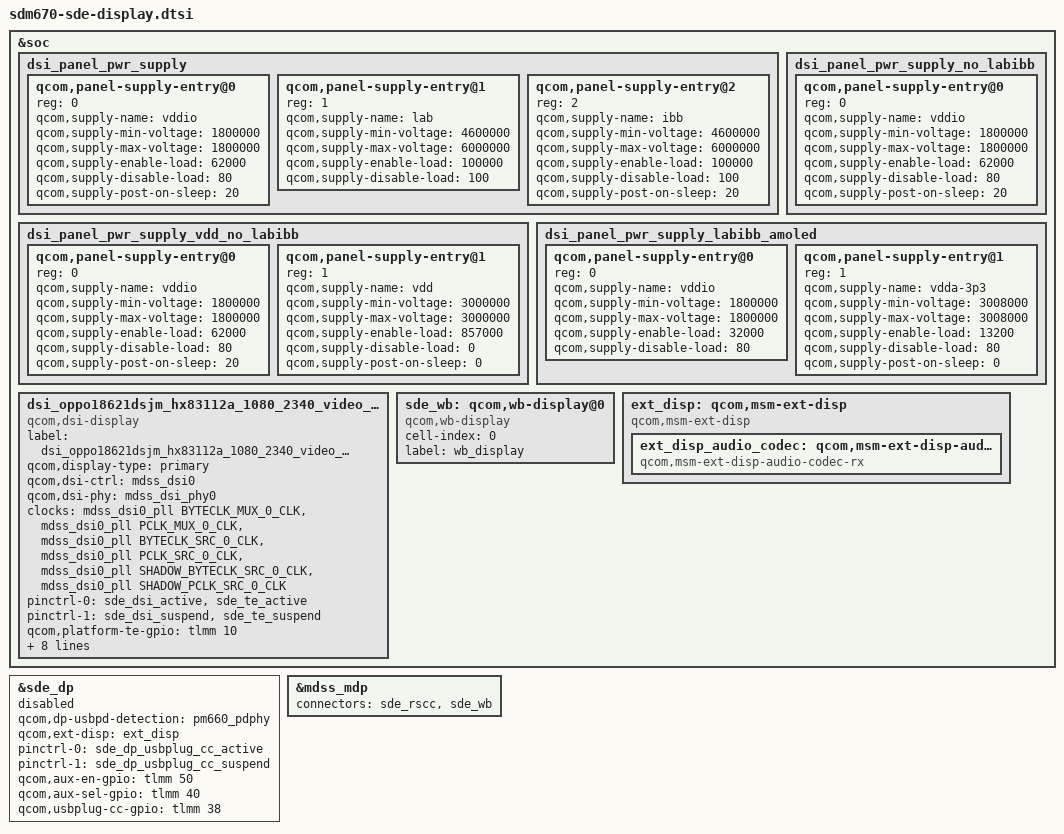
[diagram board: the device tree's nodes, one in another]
/* Copyright (c) 2017-2019, The Linux Foundation. All rights reserved.
 *
 * This program is free software; you can redistribute it and/or modify
 * it under the terms of the GNU General Public License version 2 and
 * only version 2 as published by the Free Software Foundation.
 *
 * This program is distributed in the hope that it will be useful,
 * but WITHOUT ANY WARRANTY; without even the implied warranty of
 * MERCHANTABILITY or FITNESS FOR A PARTICULAR PURPOSE.  See the
 * GNU General Public License for more details.
 */

#include <dt-bindings/clock/mdss-10nm-pll-clk.h>
//#ifdef OPLUS_BUG_STABILITY
#include "dsi-panel_oppo18621dsjm_hx83112a_1080_2340_video.dtsi"
//#endif

&soc {
	dsi_panel_pwr_supply: dsi_panel_pwr_supply {
		#address-cells = <1>;
		#size-cells = <0>;

		qcom,panel-supply-entry@0 {
			reg = <0>;
			qcom,supply-name = "vddio";
			qcom,supply-min-voltage = <1800000>;
			qcom,supply-max-voltage = <1800000>;
			qcom,supply-enable-load = <62000>;
			qcom,supply-disable-load = <80>;
			qcom,supply-post-on-sleep = <20>;
		};

		qcom,panel-supply-entry@1 {
			reg = <1>;
			qcom,supply-name = "lab";
			qcom,supply-min-voltage = <4600000>;
			qcom,supply-max-voltage = <6000000>;
			qcom,supply-enable-load = <100000>;
			qcom,supply-disable-load = <100>;
		};

		qcom,panel-supply-entry@2 {
			reg = <2>;
			qcom,supply-name = "ibb";
			qcom,supply-min-voltage = <4600000>;
			qcom,supply-max-voltage = <6000000>;
			qcom,supply-enable-load = <100000>;
			qcom,supply-disable-load = <100>;
			qcom,supply-post-on-sleep = <20>;
		};
	};

	dsi_panel_pwr_supply_no_labibb: dsi_panel_pwr_supply_no_labibb {
		#address-cells = <1>;
		#size-cells = <0>;

		qcom,panel-supply-entry@0 {
			reg = <0>;
			qcom,supply-name = "vddio";
			qcom,supply-min-voltage = <1800000>;
			qcom,supply-max-voltage = <1800000>;
			qcom,supply-enable-load = <62000>;
			qcom,supply-disable-load = <80>;
			qcom,supply-post-on-sleep = <20>;
		};
	};

	dsi_panel_pwr_supply_vdd_no_labibb: dsi_panel_pwr_supply_vdd_no_labibb {
		#address-cells = <1>;
		#size-cells = <0>;

		qcom,panel-supply-entry@0 {
			reg = <0>;
			qcom,supply-name = "vddio";
			qcom,supply-min-voltage = <1800000>;
			qcom,supply-max-voltage = <1800000>;
			qcom,supply-enable-load = <62000>;
			qcom,supply-disable-load = <80>;
			qcom,supply-post-on-sleep = <20>;
		};

		qcom,panel-supply-entry@1 {
			reg = <1>;
			qcom,supply-name = "vdd";
			qcom,supply-min-voltage = <3000000>;
			qcom,supply-max-voltage = <3000000>;
			qcom,supply-enable-load = <857000>;
			qcom,supply-disable-load = <0>;
			qcom,supply-post-on-sleep = <0>;
		};
	};

	dsi_panel_pwr_supply_labibb_amoled: dsi_panel_pwr_supply_labibb_amoled {
		#address-cells = <1>;
		#size-cells = <0>;

		qcom,panel-supply-entry@0 {
			reg = <0>;
			qcom,supply-name = "vddio";
			qcom,supply-min-voltage = <1800000>;
			qcom,supply-max-voltage = <1800000>;
			qcom,supply-enable-load = <32000>;
			qcom,supply-disable-load = <80>;
		};

		qcom,panel-supply-entry@1 {
			reg = <1>;
			qcom,supply-name = "vdda-3p3";
			qcom,supply-min-voltage = <3300000>;
			qcom,supply-max-voltage = <3300000>;
			qcom,supply-enable-load = <13200>;
			qcom,supply-disable-load = <80>;
		};
	};

    //#ifdef OPLUS_BUG_STABILITY
	dsi_oppo18621dsjm_hx83112a_1080_2340_video_display: qcom,dsi-display@22 {
		compatible = "qcom,dsi-display";
		label = "dsi_oppo18621dsjm_hx83112a_1080_2340_video_display";
		qcom,display-type = "primary";

		qcom,dsi-ctrl = <&mdss_dsi0>;
		qcom,dsi-phy = <&mdss_dsi_phy0>;
		clocks = <&mdss_dsi0_pll BYTECLK_MUX_0_CLK>,
			 <&mdss_dsi0_pll PCLK_MUX_0_CLK>,
			 <&mdss_dsi0_pll BYTECLK_SRC_0_CLK>,
			 <&mdss_dsi0_pll PCLK_SRC_0_CLK>,
			 <&mdss_dsi0_pll SHADOW_BYTECLK_SRC_0_CLK>,
			 <&mdss_dsi0_pll SHADOW_PCLK_SRC_0_CLK>;
		clock-names = "mux_byte_clk", "mux_pixel_clk",
			      "src_byte_clk", "src_pixel_clk",
			      "shadow_byte_clk", "shadow_pixel_clk";

		pinctrl-names = "panel_active", "panel_suspend";
		pinctrl-0 = <&sde_dsi_active &sde_te_active>;
		pinctrl-1 = <&sde_dsi_suspend &sde_te_suspend>;
		qcom,platform-te-gpio = <&tlmm 10 0>;
		qcom,platform-reset-gpio = <&tlmm 26 0>;
                qcom,platform-en-gpio = <&tlmm 4 0>;
		qcom,dsi-display-active;

		qcom,dsi-panel = <&dsi_oppo18316himax_hx83112a_1080_2340_video>;
		vddio-supply = <&pm660_l8>;
		lab-supply = <&lcdb_ldo_vreg>;
		ibb-supply = <&lcdb_ncp_vreg>;
	};
	//#endif /* OPLUS_BUG_STABILITY *

	sde_wb: qcom,wb-display@0 {
		compatible = "qcom,wb-display";
		cell-index = <0>;
		label = "wb_display";
	};

	ext_disp: qcom,msm-ext-disp {
		compatible = "qcom,msm-ext-disp";

		ext_disp_audio_codec: qcom,msm-ext-disp-audio-codec-rx {
			compatible = "qcom,msm-ext-disp-audio-codec-rx";
		};
	};
};

&sde_dp {
	qcom,dp-usbpd-detection = <&pm660_pdphy>;
	qcom,ext-disp = <&ext_disp>;

	pinctrl-names = "mdss_dp_active", "mdss_dp_sleep";
	pinctrl-0 = <&sde_dp_aux_active &sde_dp_usbplug_cc_active>;
	pinctrl-1 = <&sde_dp_aux_suspend &sde_dp_usbplug_cc_suspend>;
	qcom,aux-en-gpio = <&tlmm 50 0>;
	qcom,aux-sel-gpio = <&tlmm 40 0>;
	qcom,usbplug-cc-gpio = <&tlmm 38 0>;
};

&mdss_mdp {
	//#ifdef OPLUS_BUG_STABILITY
	connectors = <&sde_rscc &sde_wb>;
	//#else
	//connectors = <&sde_rscc &sde_wb &sde_dp>;
	//#endif
};

//#ifdef OPLUS_BUG_STABILITY
&dsi_panel_pwr_supply_labibb_amoled {
	qcom,panel-supply-entry@1 {
		qcom,supply-min-voltage = <3008000>;
		qcom,supply-max-voltage = <3008000>;
		qcom,supply-post-on-sleep = <0>;
	};
};

&sde_dp{
	status = "disabled";

	pinctrl-0 = <&sde_dp_usbplug_cc_active>;
	pinctrl-1 = <&sde_dp_usbplug_cc_suspend>;

	qcom,usbplug-cc-gpio = <&tlmm 38 0>;
	/delete-node/ qcom,aux-en-gpio;
	/delete-node/ qcom,aux-sel-gpio;
};
//#endif
